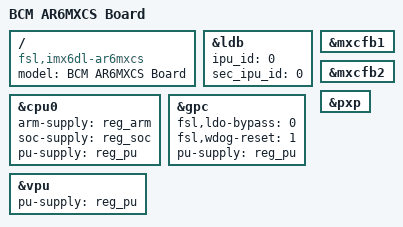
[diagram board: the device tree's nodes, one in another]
/*
 * Copyright (C) 2014 BCM Advanced Research
 *
 * This program is free software; you can redistribute it and/or modify
 * it under the terms of the GNU General Public License version 2 as
 * published by the Free Software Foundation.
 */

/ {
	model = "BCM AR6MXCS Board";
	compatible = "fsl,imx6dl-ar6mxcs", "fsl,imx6dl";
};

&ldb {
	ipu_id = <0>;
	sec_ipu_id = <0>;
};

&mxcfb1 {
	status = "okay";
};

&mxcfb2 {
	status = "okay";
};

&pxp {
	status = "okay";
};

&cpu0 {
	arm-supply = <&reg_arm>;
	soc-supply = <&reg_soc>;
	pu-supply = <&reg_pu>; /* use pu_dummy if VDDSOC share with VDDPU */
};

&gpc {
	fsl,ldo-bypass = <0>; /* use ldo-bypass, u-boot will check it and configure */
	fsl,wdog-reset = <1>; /* watchdog select of reset source */
	pu-supply = <&reg_pu>; /* ldo-bypass:use pu_dummy if VDDSOC share with VDDPU */
};

&vpu {
	pu-supply = <&reg_pu>; /* ldo-bypass:use pu_dummy if VDDSOC share with VDDPU */
};
